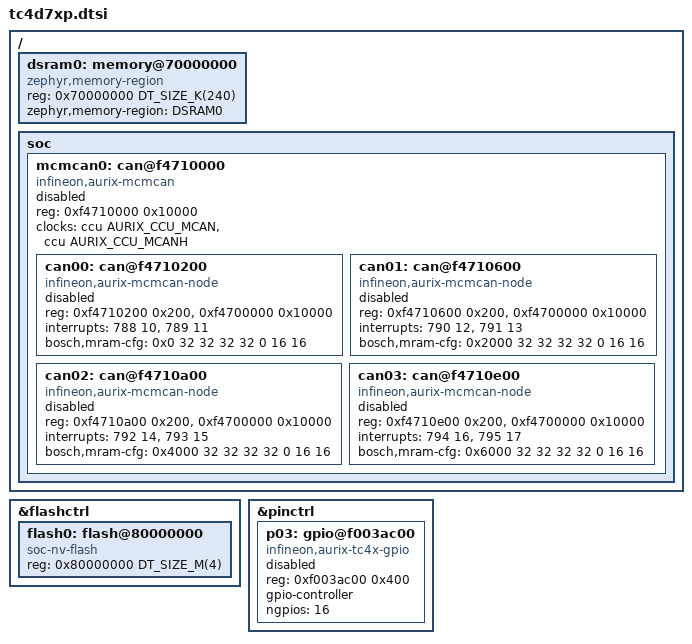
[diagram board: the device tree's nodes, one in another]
/*
 * SPDX-FileCopyrightText: Copyright (c) 2024 Infineon Technologies AG,
 * SPDX-FileCopyrightText: or an affiliate of Infineon Technologies AG. All rights reserved.
 * SPDX-FileCopyrightText: Copyright (c) 2026 Linumiz
 *
 * SPDX-License-Identifier: Apache-2.0
 */

#include <infineon/tc4x/tc4x.dtsi>

/ {
	/* Data scratch-pad RAM of CPU0 */
	dsram0: memory@70000000 {
		compatible = "zephyr,memory-region", "mmio-sram";
		reg = <0x70000000 DT_SIZE_K(240)>;
		zephyr,memory-region = "DSRAM0";
	};
};

&flashctrl {
	flash0: flash@80000000 {
		compatible = "soc-nv-flash";
		reg = <0x80000000 DT_SIZE_M(4)>;
		ranges = <0x0 0x80000000 DT_SIZE_M(4)>;
		#address-cells = <1>;
		#size-cells = <1>;
	};
};

&pinctrl {
	p03: gpio@f003ac00 {
		compatible = "infineon,aurix-tc4x-gpio", "infineon,aurix-gpio";
		reg = <0xf003ac00 0x400>;
		gpio-controller;
		#gpio-cells = <2>;
		ngpios = <16>;
		status = "disabled";
	};
};

/ {
	soc {
		mcmcan0: can@f4710000 {
			compatible = "infineon,aurix-mcmcan";
			reg = <0xf4710000 0x10000>;
			clocks = <&ccu AURIX_CCU_MCAN>, <&ccu AURIX_CCU_MCANH>;
			clock-names = "mcan", "mcanh";
			#address-cells = <1>;
			#size-cells = <1>;
			ranges;
			status = "disabled";

			can00: can@f4710200 {
				compatible = "infineon,aurix-mcmcan-node";
				reg = <0xf4710200 0x200>, <0xf4700000 0x10000>;
				reg-names = "m_can", "message_ram";
				interrupts = <788 10>, <789 11>;
				interrupt-names = "line0", "line1";
				bosch,mram-cfg = <0x0 32 32 32 32 0 16 16>;
				status = "disabled";
			};

			can01: can@f4710600 {
				compatible = "infineon,aurix-mcmcan-node";
				reg = <0xf4710600 0x200>, <0xf4700000 0x10000>;
				reg-names = "m_can", "message_ram";
				interrupts = <790 12>, <791 13>;
				interrupt-names = "line0", "line1";
				bosch,mram-cfg = <0x2000 32 32 32 32 0 16 16>;
				status = "disabled";
			};

			can02: can@f4710a00 {
				compatible = "infineon,aurix-mcmcan-node";
				reg = <0xf4710a00 0x200>, <0xf4700000 0x10000>;
				reg-names = "m_can", "message_ram";
				interrupts = <792 14>, <793 15>;
				interrupt-names = "line0", "line1";
				bosch,mram-cfg = <0x4000 32 32 32 32 0 16 16>;
				status = "disabled";
			};

			can03: can@f4710e00 {
				compatible = "infineon,aurix-mcmcan-node";
				reg = <0xf4710e00 0x200>, <0xf4700000 0x10000>;
				reg-names = "m_can", "message_ram";
				interrupts = <794 16>, <795 17>;
				interrupt-names = "line0", "line1";
				bosch,mram-cfg = <0x6000 32 32 32 32 0 16 16>;
				status = "disabled";
			};
		};
	};
};
